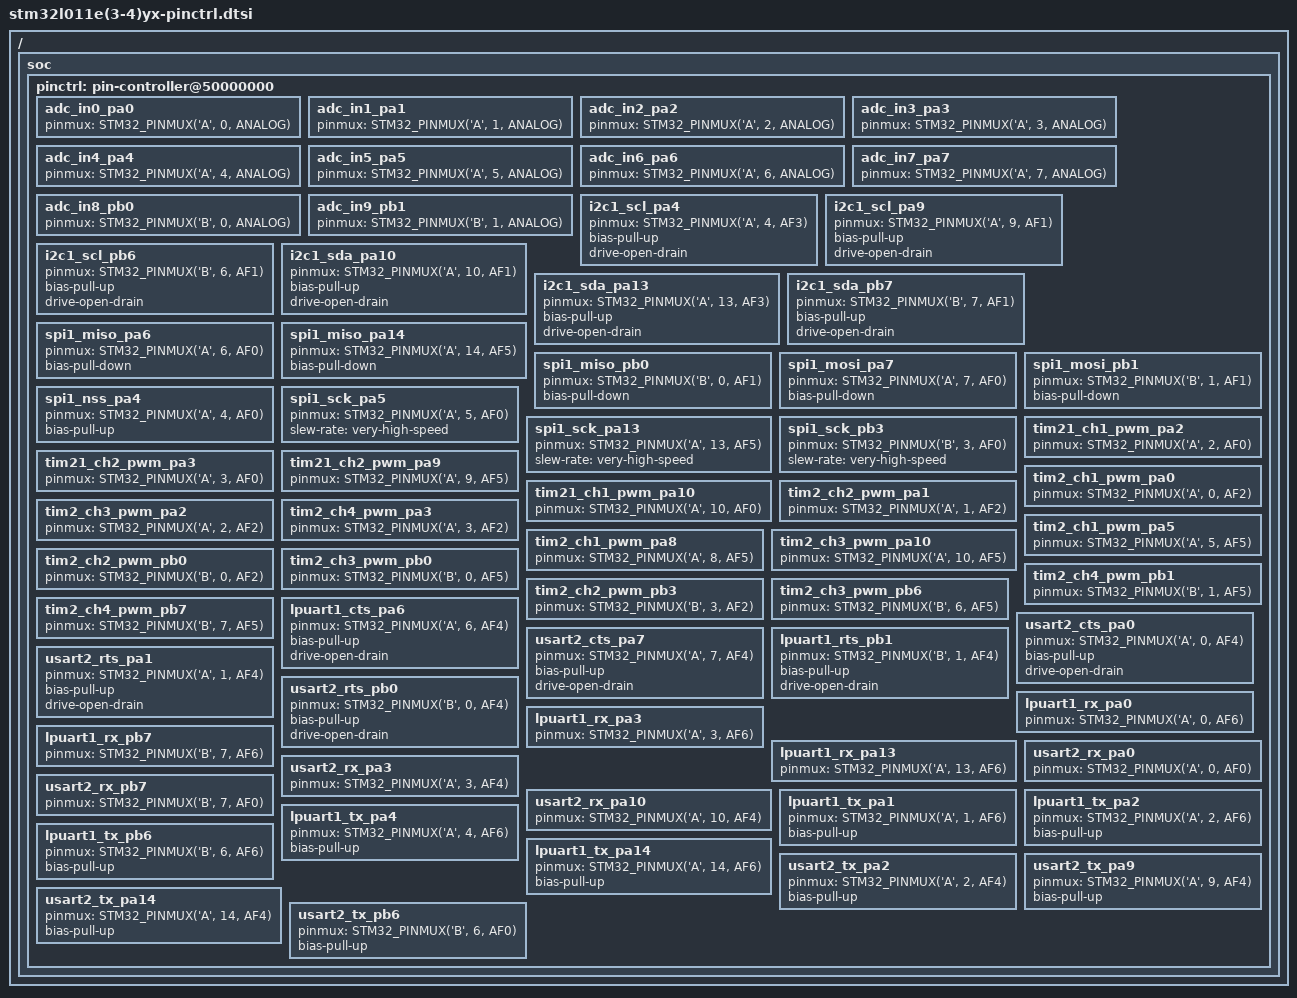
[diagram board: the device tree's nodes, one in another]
/*
 * NOTE: Autogenerated file using genpinctrl.py
 *
 * SPDX-License-Identifier: Apache-2.0
 */

#include <dt-bindings/pinctrl/stm32-pinctrl.h>

/ {
	soc {
		pinctrl: pin-controller@50000000 {

			/* ADC_IN / ADC_INN / ADC_INP */

			adc_in0_pa0: adc_in0_pa0 {
				pinmux = <STM32_PINMUX('A', 0, ANALOG)>;
			};

			adc_in1_pa1: adc_in1_pa1 {
				pinmux = <STM32_PINMUX('A', 1, ANALOG)>;
			};

			adc_in2_pa2: adc_in2_pa2 {
				pinmux = <STM32_PINMUX('A', 2, ANALOG)>;
			};

			adc_in3_pa3: adc_in3_pa3 {
				pinmux = <STM32_PINMUX('A', 3, ANALOG)>;
			};

			adc_in4_pa4: adc_in4_pa4 {
				pinmux = <STM32_PINMUX('A', 4, ANALOG)>;
			};

			adc_in5_pa5: adc_in5_pa5 {
				pinmux = <STM32_PINMUX('A', 5, ANALOG)>;
			};

			adc_in6_pa6: adc_in6_pa6 {
				pinmux = <STM32_PINMUX('A', 6, ANALOG)>;
			};

			adc_in7_pa7: adc_in7_pa7 {
				pinmux = <STM32_PINMUX('A', 7, ANALOG)>;
			};

			adc_in8_pb0: adc_in8_pb0 {
				pinmux = <STM32_PINMUX('B', 0, ANALOG)>;
			};

			adc_in9_pb1: adc_in9_pb1 {
				pinmux = <STM32_PINMUX('B', 1, ANALOG)>;
			};

			/* I2C_SCL */

			i2c1_scl_pa4: i2c1_scl_pa4 {
				pinmux = <STM32_PINMUX('A', 4, AF3)>;
				bias-pull-up;
				drive-open-drain;
			};

			i2c1_scl_pa9: i2c1_scl_pa9 {
				pinmux = <STM32_PINMUX('A', 9, AF1)>;
				bias-pull-up;
				drive-open-drain;
			};

			i2c1_scl_pb6: i2c1_scl_pb6 {
				pinmux = <STM32_PINMUX('B', 6, AF1)>;
				bias-pull-up;
				drive-open-drain;
			};

			/* I2C_SDA */

			i2c1_sda_pa10: i2c1_sda_pa10 {
				pinmux = <STM32_PINMUX('A', 10, AF1)>;
				bias-pull-up;
				drive-open-drain;
			};

			i2c1_sda_pa13: i2c1_sda_pa13 {
				pinmux = <STM32_PINMUX('A', 13, AF3)>;
				bias-pull-up;
				drive-open-drain;
			};

			i2c1_sda_pb7: i2c1_sda_pb7 {
				pinmux = <STM32_PINMUX('B', 7, AF1)>;
				bias-pull-up;
				drive-open-drain;
			};

			/* SPI_MISO */

			spi1_miso_pa6: spi1_miso_pa6 {
				pinmux = <STM32_PINMUX('A', 6, AF0)>;
				bias-pull-down;
			};

			spi1_miso_pa14: spi1_miso_pa14 {
				pinmux = <STM32_PINMUX('A', 14, AF5)>;
				bias-pull-down;
			};

			spi1_miso_pb0: spi1_miso_pb0 {
				pinmux = <STM32_PINMUX('B', 0, AF1)>;
				bias-pull-down;
			};

			/* SPI_MOSI */

			spi1_mosi_pa7: spi1_mosi_pa7 {
				pinmux = <STM32_PINMUX('A', 7, AF0)>;
				bias-pull-down;
			};

			spi1_mosi_pb1: spi1_mosi_pb1 {
				pinmux = <STM32_PINMUX('B', 1, AF1)>;
				bias-pull-down;
			};

			/* SPI_NSS */

			spi1_nss_pa4: spi1_nss_pa4 {
				pinmux = <STM32_PINMUX('A', 4, AF0)>;
				bias-pull-up;
			};

			/* SPI_SCK */

			spi1_sck_pa5: spi1_sck_pa5 {
				pinmux = <STM32_PINMUX('A', 5, AF0)>;
				slew-rate = "very-high-speed";
			};

			spi1_sck_pa13: spi1_sck_pa13 {
				pinmux = <STM32_PINMUX('A', 13, AF5)>;
				slew-rate = "very-high-speed";
			};

			spi1_sck_pb3: spi1_sck_pb3 {
				pinmux = <STM32_PINMUX('B', 3, AF0)>;
				slew-rate = "very-high-speed";
			};

			/* TIM_CH_PWM / TIM_CHN_PWM */

			tim21_ch1_pwm_pa2: tim21_ch1_pwm_pa2 {
				pinmux = <STM32_PINMUX('A', 2, AF0)>;
			};

			tim21_ch2_pwm_pa3: tim21_ch2_pwm_pa3 {
				pinmux = <STM32_PINMUX('A', 3, AF0)>;
			};

			tim21_ch2_pwm_pa9: tim21_ch2_pwm_pa9 {
				pinmux = <STM32_PINMUX('A', 9, AF5)>;
			};

			tim21_ch1_pwm_pa10: tim21_ch1_pwm_pa10 {
				pinmux = <STM32_PINMUX('A', 10, AF0)>;
			};

			tim2_ch1_pwm_pa0: tim2_ch1_pwm_pa0 {
				pinmux = <STM32_PINMUX('A', 0, AF2)>;
			};

			tim2_ch2_pwm_pa1: tim2_ch2_pwm_pa1 {
				pinmux = <STM32_PINMUX('A', 1, AF2)>;
			};

			tim2_ch3_pwm_pa2: tim2_ch3_pwm_pa2 {
				pinmux = <STM32_PINMUX('A', 2, AF2)>;
			};

			tim2_ch4_pwm_pa3: tim2_ch4_pwm_pa3 {
				pinmux = <STM32_PINMUX('A', 3, AF2)>;
			};

			tim2_ch1_pwm_pa5: tim2_ch1_pwm_pa5 {
				pinmux = <STM32_PINMUX('A', 5, AF5)>;
			};

			tim2_ch1_pwm_pa8: tim2_ch1_pwm_pa8 {
				pinmux = <STM32_PINMUX('A', 8, AF5)>;
			};

			tim2_ch3_pwm_pa10: tim2_ch3_pwm_pa10 {
				pinmux = <STM32_PINMUX('A', 10, AF5)>;
			};

			tim2_ch2_pwm_pb0: tim2_ch2_pwm_pb0 {
				pinmux = <STM32_PINMUX('B', 0, AF2)>;
			};

			tim2_ch3_pwm_pb0: tim2_ch3_pwm_pb0 {
				pinmux = <STM32_PINMUX('B', 0, AF5)>;
			};

			tim2_ch4_pwm_pb1: tim2_ch4_pwm_pb1 {
				pinmux = <STM32_PINMUX('B', 1, AF5)>;
			};

			tim2_ch2_pwm_pb3: tim2_ch2_pwm_pb3 {
				pinmux = <STM32_PINMUX('B', 3, AF2)>;
			};

			tim2_ch3_pwm_pb6: tim2_ch3_pwm_pb6 {
				pinmux = <STM32_PINMUX('B', 6, AF5)>;
			};

			tim2_ch4_pwm_pb7: tim2_ch4_pwm_pb7 {
				pinmux = <STM32_PINMUX('B', 7, AF5)>;
			};

			/* UART_CTS / USART_CTS / LPUART_CTS */

			lpuart1_cts_pa6: lpuart1_cts_pa6 {
				pinmux = <STM32_PINMUX('A', 6, AF4)>;
				bias-pull-up;
				drive-open-drain;
			};

			usart2_cts_pa0: usart2_cts_pa0 {
				pinmux = <STM32_PINMUX('A', 0, AF4)>;
				bias-pull-up;
				drive-open-drain;
			};

			usart2_cts_pa7: usart2_cts_pa7 {
				pinmux = <STM32_PINMUX('A', 7, AF4)>;
				bias-pull-up;
				drive-open-drain;
			};

			/* UART_RTS / USART_RTS / LPUART_RTS */

			lpuart1_rts_pb1: lpuart1_rts_pb1 {
				pinmux = <STM32_PINMUX('B', 1, AF4)>;
				bias-pull-up;
				drive-open-drain;
			};

			usart2_rts_pa1: usart2_rts_pa1 {
				pinmux = <STM32_PINMUX('A', 1, AF4)>;
				bias-pull-up;
				drive-open-drain;
			};

			usart2_rts_pb0: usart2_rts_pb0 {
				pinmux = <STM32_PINMUX('B', 0, AF4)>;
				bias-pull-up;
				drive-open-drain;
			};

			/* UART_RX / USART_RX / LPUART_RX */

			lpuart1_rx_pa0: lpuart1_rx_pa0 {
				pinmux = <STM32_PINMUX('A', 0, AF6)>;
			};

			lpuart1_rx_pa3: lpuart1_rx_pa3 {
				pinmux = <STM32_PINMUX('A', 3, AF6)>;
			};

			lpuart1_rx_pa13: lpuart1_rx_pa13 {
				pinmux = <STM32_PINMUX('A', 13, AF6)>;
			};

			lpuart1_rx_pb7: lpuart1_rx_pb7 {
				pinmux = <STM32_PINMUX('B', 7, AF6)>;
			};

			usart2_rx_pa0: usart2_rx_pa0 {
				pinmux = <STM32_PINMUX('A', 0, AF0)>;
			};

			usart2_rx_pa3: usart2_rx_pa3 {
				pinmux = <STM32_PINMUX('A', 3, AF4)>;
			};

			usart2_rx_pa10: usart2_rx_pa10 {
				pinmux = <STM32_PINMUX('A', 10, AF4)>;
			};

			usart2_rx_pb7: usart2_rx_pb7 {
				pinmux = <STM32_PINMUX('B', 7, AF0)>;
			};

			/* UART_TX / USART_TX / LPUART_TX */

			lpuart1_tx_pa1: lpuart1_tx_pa1 {
				pinmux = <STM32_PINMUX('A', 1, AF6)>;
				bias-pull-up;
			};

			lpuart1_tx_pa2: lpuart1_tx_pa2 {
				pinmux = <STM32_PINMUX('A', 2, AF6)>;
				bias-pull-up;
			};

			lpuart1_tx_pa4: lpuart1_tx_pa4 {
				pinmux = <STM32_PINMUX('A', 4, AF6)>;
				bias-pull-up;
			};

			lpuart1_tx_pa14: lpuart1_tx_pa14 {
				pinmux = <STM32_PINMUX('A', 14, AF6)>;
				bias-pull-up;
			};

			lpuart1_tx_pb6: lpuart1_tx_pb6 {
				pinmux = <STM32_PINMUX('B', 6, AF6)>;
				bias-pull-up;
			};

			usart2_tx_pa2: usart2_tx_pa2 {
				pinmux = <STM32_PINMUX('A', 2, AF4)>;
				bias-pull-up;
			};

			usart2_tx_pa9: usart2_tx_pa9 {
				pinmux = <STM32_PINMUX('A', 9, AF4)>;
				bias-pull-up;
			};

			usart2_tx_pa14: usart2_tx_pa14 {
				pinmux = <STM32_PINMUX('A', 14, AF4)>;
				bias-pull-up;
			};

			usart2_tx_pb6: usart2_tx_pb6 {
				pinmux = <STM32_PINMUX('B', 6, AF0)>;
				bias-pull-up;
			};

		};
	};
};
